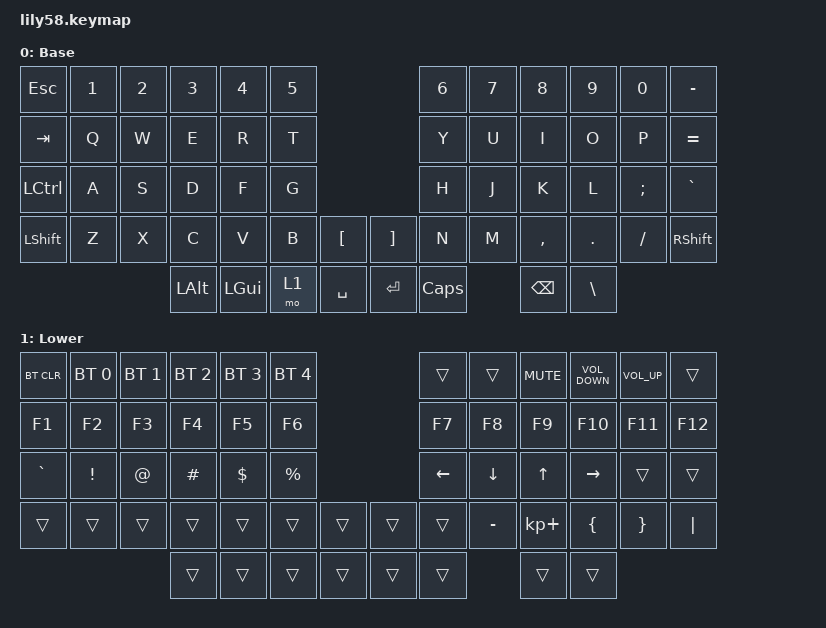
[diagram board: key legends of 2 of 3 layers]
/*
 * Copyright (c) 2020 The ZMK Contributors
 *
 * SPDX-License-Identifier: MIT
 */

#include <behaviors.dtsi>
#include <dt-bindings/zmk/keys.h>
#include <dt-bindings/zmk/bt.h>
#include <dt-bindings/zmk/ext_power.h>

/ {


    behaviors {
        custom_md: mod_tap {
            compatible = "zmk,behavior-hold-tap";
            #binding-cells = <2>;
            flavor = "hold-preferred";
            tapping-term-ms = <200>;
            bindings = <&mo>, <&to>;
            display-name = "Custom MD";
        };

        // ь/Ь → ъ/Ъ при Alt
        ru_soft: ru_soft_hard {
            compatible = "zmk,behavior-mod-morph";
            #binding-cells = <0>;
            bindings = <&uc UC_RU_SOFT>, <&uc UC_RU_HARD>;
            mods = <(MOD_LALT|MOD_RALT)>;
        };
    };

    keymap {
        compatible = "zmk,keymap";

        default_layer {
// ------------------------------------------------------------------------------------------------------------
// |  ESC  |  1  |  2  |  3   |  4   |  5   |                   |  6   |  7    |  8    |  9   |   0   |   -   |
// |  TAB  |  Q  |  W  |  E   |  R   |  T   |                   |  Y   |  U    |  I    |  O   |   P   |   =   |
// |  CTRL |  A  |  S  |  D   |  F   |  G   |                   |  H   |  J    |  K    |  L   |   ~   |   '   |
// | SHIFT |  Z  |  X  |  C   |  V   |  B   |   ","  |  |  "."  |  N   |  M    |  &    |  [   |   ]   |   /   |
//                     | ALT  | GUI  | LOWER|  SPACE |  | ENTER | RAISE| BSPC  | GUI   |
            display-name = "Base";
            bindings = <
&kp ESC   &kp N1 &kp N2 &kp N3   &kp N4   &kp N5                     &kp N6 &kp N7   &kp N8    &kp N9  &kp N0   &kp MINUS
&kp TAB   &kp Q  &kp W  &kp E    &kp R    &kp T                      &kp Y  &kp U    &kp I     &kp O   &kp P    &kp EQUAL
&kp LCTRL &kp A  &kp S  &kp D    &kp F    &kp G                      &kp H  &kp J    &kp K     &kp L   &kp SEMI &kp GRAVE
&kp LSHFT &kp Z  &kp X  &kp C    &kp V    &kp B  &kp LBKT   &kp RBKT &kp N  &kp M    &kp COMMA &kp DOT &kp FSLH &kp RSHFT
                        &kp LALT &kp LGUI &mo 1  &kp SPACE  &kp RET  &kp CAPSLOCK    &kp BSPC  &kp BSLH
            >;

            sensor-bindings = <&inc_dec_kp C_VOL_UP C_VOL_DN>;
        };

        lower_layer {
// ------------------------------------------------------------------------------------------------------------
// | BTCLR | BT1 | BT2 |  BT3 |  BT4 |  BT5 |                   |      |       |       |      |       |       |
// |  F1   |  F2 |  F3 |  F4  |  F5  |  F6  |                   |  F7  |  F8   |  F9   |  F10 |  F11  |  F12  |
// |   `   |  !  |  @  |  #   |  $   |  %   |                   |  ^   |  &    |  *    |  (   |   )   |   ~   |
// |       |     |     |      |      |      |        |  |       |      |  _    |  +    |  {   |   }   |  "|"  |
//                     |      |      |      |        |  |       |      |       |       |
            display-name = "Lower";
            bindings = <
&bt BT_CLR &bt BT_SEL 0     &bt BT_SEL 1      &bt BT_SEL 2      &bt BT_SEL 3 &bt BT_SEL 4                 &trans      &trans    &kp C_MUTE      &kp C_VOLUME_DOWN  &kp C_VOLUME_UP  &trans
&kp F1     &kp F2           &kp F3            &kp F4            &kp F5       &kp F6                       &kp F7      &kp F8    &kp F9          &kp F10            &kp F11          &kp F12
&kp GRAVE  &kp EXCL         &kp AT            &kp HASH          &kp DOLLAR   &kp PRCNT                    &kp LEFT    &kp DOWN  &kp UP          &kp RIGHT          &trans           &trans
&trans     &trans           &trans            &trans            &trans       &trans    &trans   &trans    &trans      &kp MINUS &kp KP_PLUS     &kp LBRC           &kp RBRC         &kp PIPE
                                              &trans            &trans       &trans    &trans   &trans    &trans      &trans    &trans
            >;

            sensor-bindings = <&inc_dec_kp C_VOL_UP C_VOL_DN>;
        };

        raise_layer {
// ------------------------------------------------------------------------------------------------------------
// |       |     |     |      |      |      |                   |      |       |       |      |       |       |
// |   `   |  1  |  2  |  3   |  4   |  5   |                   |  6   |   7   |   8   |  9   |   0   |       |
// |   F1  |  F2 |  F3 |  F4  |  F5  |  F6  |                   |      |   <-  |   v   |  ^   |  ->   |       |
// |   F7  |  F8 |  F9 |  F10 |  F11 |  F12 |        |  |       |  +   |   -   |   =   |  [   |   ]   |   \   |
//                     |      |      |      |        |  |       |      |       |       |
            display-name = "Raise";
            bindings = <
&trans    &trans &trans &trans  &trans  &trans                       &trans      &trans    &kp C_MUTE    &kp C_VOLUME_DOWN            &kp C_VOLUME_UP    &trans
&kp GRAVE &kp N1 &kp N2 &kp N3  &kp N4  &kp N5                       &kp N6      &kp N7    &kp N8    &kp N9   &kp N0    &trans
&kp F1    &kp F2 &kp F3 &kp F4  &kp F5  &kp F6                       &kp LEFT    &kp DOWN  &kp UP    &kp RIGHT &trans
&kp F7    &kp F8 &kp F9 &kp F10 &kp F11 &kp F12   &trans   &trans    &kp KP_PLUS &kp MINUS &kp EQUAL &kp LBKT &kp RBKT  &kp BSLH
                        &trans  &trans  &trans    &trans   &trans    &trans      &trans    &trans
            >;

            sensor-bindings = <&inc_dec_kp C_VOL_UP C_VOL_DN>;
        };

        extra_1 {
            status = "reserved";
        };

        extra_2 {
            status = "reserved";
        };

        extra_3 {
            status = "reserved";
        };
    };
};
